# A31T41x register map
Vendor: ABOV Semiconductor Co., Ltd.; File version: 1.0
CPU: CM0PLUS r0p1, little endian, no MPU, no FPU, VTOR, vendor SysTick, 2 interrupt priority bits
Registers are 32-bit, read-write, reset 0x0 unless marked. A register's access mark holds for its fields unless they carry their own. Offsets are from the block's base; [hi:lo] are bit positions; {n}, {i} and the like mark numbered series; 'fields as' and 'values as' point back to an identical list.

## CFMC — CODE FLASH MEMORY CONTROLLER
Base 0x40080000
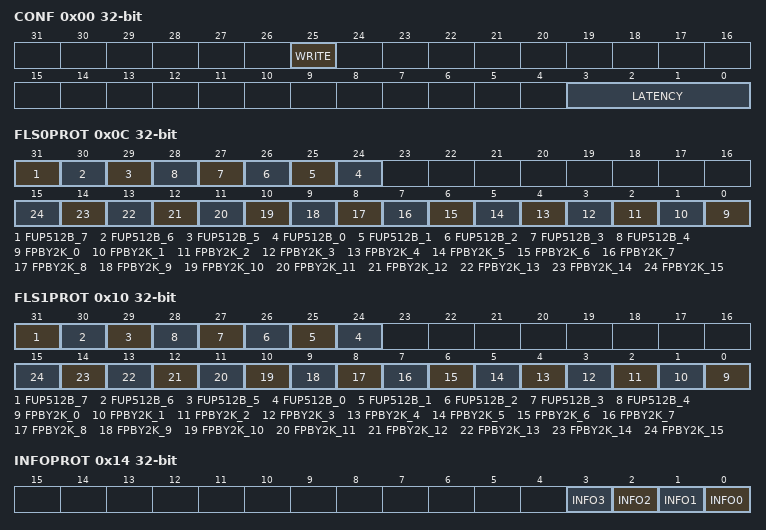
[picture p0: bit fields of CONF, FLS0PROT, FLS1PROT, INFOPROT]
0x00 CONF — code flash control register
  [25] WRITE — Code Flash write Enable Bit
    0=Disable write; 1=Enable write
  [3:0] LATENCY — Flash Wait Value Bits
0x04 FLSKEY wo — code flash access key register
  [31:0] FKEY — These bits are the key values used to access the flash memory, KEY1(0x01234567) -> KEY2(0x12345678) -> KEY3(0x23456789)
0x08 INFOKEY wo — code flash User info access key register
  [31:0] INFOKEY — These bits are the key values used to access the flash User info area, KEY1(0x3456789A) -> KEY2(0x456789AB) -> KEY3(0x56789ABC)
0x0C FLS0PROT — code flash protection register
  [31] FUP512B_7 — Unprotection of the 0x0000_7E00 to 0x0000_7FFF of Flash memory
  [30] FUP512B_6 — Unprotection of the 0x0000_7C00 to 0x0000_7DFF of Flash memory
  [29] FUP512B_5 — Unprotection of the 0x0000_7A00 to 0x0000_7BFF of Flash memory
  [n+24] FUP512B_{n} (n=0..4) — Unprotection of the 0x0000_{200n+7000} to 0x0000_{2n+71}FF of Flash memory
  [n] FPBY2K_{n} (n=0..15) — Flash area protection selection bit
0x10 FLS1PROT — code flash protection register
  fields as FLS0PROT
0x14 INFOPROT — code flash info protection register
  [n] INFO{n} (n=0..3) — INFO{n} Area Protection bit, 0x0F00_{200n:04} 0x0F00_{2n+1:02}FF
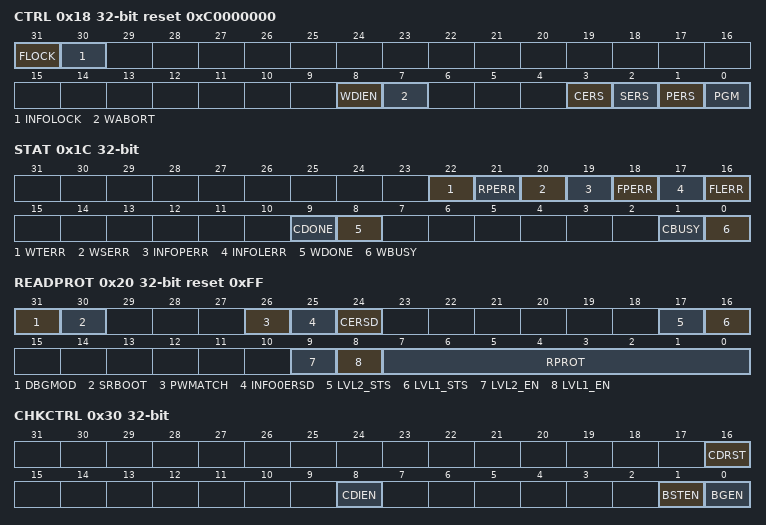
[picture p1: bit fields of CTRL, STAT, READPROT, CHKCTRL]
0x18 CTRL reset 0xC0000000 — code flash access control register
  [31] FLOCK — Code flash access control bit
  [30] INFOLOCK — User info access control bit
  [8] WDIEN — Write done interrupt enable
    0=Disable interrupt; 1=Enable interrupt
  [7] WABORT — Write abort settings
    0=Disable (No Effect); 1=Enable (Abort write operation)
  [3] CERS — Whole flash memory erase
    0=Disable bulk erase; 1=Enable bulk erase
  [2] SERS — Flash memory erase in sector units
    0=Disable sector erase; 1=Enable sector erase
  [1] PERS — Flash memory erase in page units
    0=Disable page erase; 1=Enable page erase
  [0] PGM — Program Mode
    0=Disable program; 1=Enable program
0x1C STAT — code flash access status register
  [22] WTERR — Write timeout error (cleared by writing a '1')
  [21] RPERR — Read-protect error (cleared by writing a '1')
  [20] WSERR — Write sequence error (cleared by writing a '1')
  [19] INFOPERR — INFO protect error (auto cleared)
  [18] FPERR — Flash protect error (auto cleared)
  [17] INFOLERR — INFO protect error (auto cleared)
  [16] FLERR — Flash lock error (auto cleared)
  [9] CDONE — CRC check done check
  [8] WDONE — Write done interrupt status (cleared by writing a '1')
  [1] CBUSY — CRC check busy check
    0=Not_Busy; 1=Busy
  [0] WBUSY ro — Write Busy Check
    0=Not_Busy; 1=Busy
0x20 READPROT reset 0xFF — Flash Read Protection Register
  [31] DBGMOD ro — Debug operating status bit
  [30] SRBOOT ro — SRAM Boot mode status bit
  [26] PWMATCH ro — Password match flag bit
  [25] INFO0ERSD ro — Chip erase and User info 0 erase done flag bit
  [24] CERSD ro — Chip erase done flag bit
  [17] LVL2_STS ro — Protection Level 2 status bit in debug mode This bit can be checked in debug mode only
  [16] LVL1_STS ro — Protection Level 1 status bit in debug mode This bit can be checked in debug mode only
  [9] LVL2_EN ro — Protection Level 2 status bit
  [8] LVL1_EN ro — Protection Level 1 status bit
  [7:0] RPROT — Read protection control bit
    255=Unprotection; 185=PROT_L1_PW (Protection Level 1 Password); 57=PROT_L1 (Protection Level 1); 128=PROT_L2_PW (Protection Level 2 Password); 0=PROT_L2 (Protection Level 2)
0x24 PWIN wo — code flash password input register
  [31:0] PWIN — Password input data bit
0x30 CHKCTRL — The CFMC_CHKCTRL register is an internal flash memory CRC control register
  [16] CDRST — CRC data reset
  [8] CDIEN — CRC done interrupt
  [1] BSTEN wo — Burst mode (automatically cleared)
  [0] BGEN wo — Background mode (automatically cleared)
0x34 CHKDOUT ro reset 0xFFFF — The CFMC_CHKDOUT register is an internal flash memory CRC data output register
  [15:0] CDOUT — CRC data reset
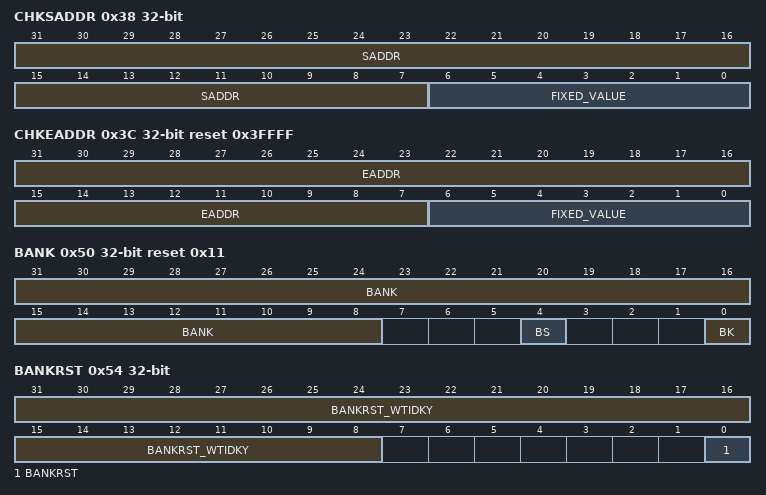
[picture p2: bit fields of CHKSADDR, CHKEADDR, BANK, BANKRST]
0x38 CHKSADDR — The CFMC_CHKSADDR register is an internal flash memory CRC start address register
  [31:7] SADDR — CRC start address value
  [6:0] FIXED_VALUE ro
0x3C CHKEADDR reset 0x3FFFF — The CFMC_CHKEADDR register is an internal flash memory CRC end address register
  [31:7] EADDR — CRC end address value
  [6:0] FIXED_VALUE ro
0x40 WTIMEOUT — code flash write time-out register
  [31:0] WTIMEOUT — Flash write time-out setting bit
0x50 BANK wo reset 0x11 — code flash bank control register
  [31:8] BANK — Bank register Identification key
  [4] BS — Bank swap (valid in bank mode)
  [0] BK — Bank mode
0x54 BANKRST wo — code flash bank reset register
  [31:8] BANKRST_WTIDKY — Bank reset register Identification key
  [0] BANKRST — Reset for bank swap (Check BANKRST in SCU_RSER for reset)
0xF18 PWPRST wo — code flash password preset register
  [31:0] PWPRST — Password preset data bit
